# IA_MPUSS register map
Vendor: Texas Instruments
Peripheral module from a debugger description file (folder omap36xx).
Registers are 64-bit, read-only, reset 0x0 unless marked. A register's access mark holds for its fields unless they carry their own. Offsets are as the file gives them; lines under a group give offsets from that group; [hi:lo] are bit positions; {n}, {i} and the like mark numbered series; 'fields as' and 'values as' point back to an identical list; <NAME> marks a mode.

## IA_MPUSS
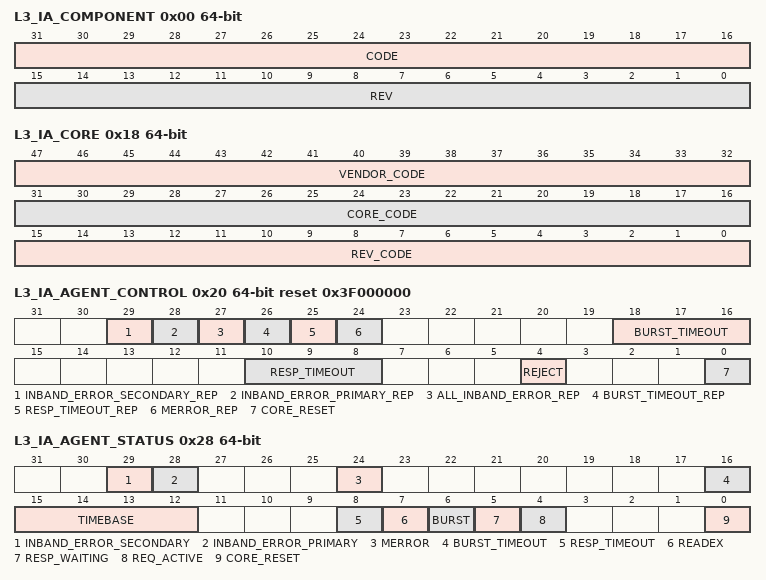
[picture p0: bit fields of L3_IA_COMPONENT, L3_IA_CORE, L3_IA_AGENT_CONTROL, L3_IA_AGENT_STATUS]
0x00 L3_IA_COMPONENT (reset mask 0xFFFFFFFF00000000) — Component register of IA
  [31:16] CODE — Component code
  [15:0] REV — Revision of the component
0x18 L3_IA_CORE (reset mask 0xFFFF000000000000) — Core register of L3 IA block
  [47:32] VENDOR_CODE
  [31:16] CORE_CODE
  [15:0] REV_CODE — Revision code
0x20 L3_IA_AGENT_CONTROL access per field reset 0x3F000000 — Agent control register of IA block
  [29] INBAND_ERROR_SECONDARY_REP rw — Reporting of in-band errors indicating debug error.Reserved for instances 3 to 12 Reserved R 0x0 .
    0=No special reporting; 1=Report error
  [28] INBAND_ERROR_PRIMARY_REP rw — Reporting of in-band errors indicating application error.
    0=No special reporting; 1=Report error
  [27] ALL_INBAND_ERROR_REP rw — Reporting of all in-band errors
    0=Only report errors that cannnot be reported in-band; 1=Report all in-band errors
  [26] BURST_TIMEOUT_REP rw — Open burst and ReadEx/Write timeout reporting
    0=No special reporting; 1=Report out of band
  [25] RESP_TIMEOUT_REP rw — Response timeout reportingReserved for instances 3, 6 to 10 and 12 Reserved R 0x00 .
    0=No special reporting; 1=Report out-of-band
  [24] MERROR_REP rw — MError reportingReserved for all instances except 14 (SGX) Reserved R 0x0000 .
    0=Suppress MError reporting; 1=Report MError
  [18:16] BURST_TIMEOUT rw — Response Timeout Bound:
    0=No timeout; 1=1x base cycles; 2=4x base cycles; 3=16x base cycles; 4=64x base cycles
  [10:8] RESP_TIMEOUT rw — Response Timeout Bound:Reserved for instances 3, 6 to 10 and 12 Reserved R 0x0 .
    values as BURST_TIMEOUT
  [4] REJECT rw — Request rejection control
    0=Normal operation; 1=Block requests from the initiator
  [0] CORE_RESET rw — Reset control for agent and reset control on core
    0=Core reset control inactive; 1=Core reset control active
0x28 L3_IA_AGENT_STATUS access per field — Agent Status Register
  [29] INBAND_ERROR_SECONDARY rw — Error Status for in-band errors indicating a debug error.Reserved for instances 3 to 12 Reserved R 0x0 .
    0=INBAND_ERROR_SECONDARY_0_r (No in-band error received); 0=INBAND_ERROR_SECONDARY_0_w (Ignored); 1=INBAND_ERROR_SECONDARY_1_r (In-band error received); 1=INBAND_ERROR_SECONDARY_1_w (Clear in-band error)
  [28] INBAND_ERROR_PRIMARY rw — Error Status for in-band errors indicating application Error
    0=INBAND_ERROR_PRIMARY_0_r (No in-band error received); 0=INBAND_ERROR_PRIMARY_0_w (Ignored); 1=INBAND_ERROR_PRIMARY_1_r (In-band error received); 1=INBAND_ERROR_PRIMARY_1_w (Clear in-band error)
  [24] MERROR ro — MErrorReserved for all instances except 14 (SGX) Reserved R 0x0000 .
    0=No Merror reported; 1=Merror asserted
  [16] BURST_TIMEOUT ro — Status of open burst and
  [15:12] TIMEBASE ro — Observation of timebase signals for internal verification
  [8] RESP_TIMEOUT ro — Response timeout statusReserved for instances 3, 6 to 10 and 12 Reserved R 0 .
  [7] READEX ro — Status of ReadEx/Write
  [6] BURST ro — Status of open burst
  [5] RESP_WAITING ro — Response WaitingReserved for instance 3,5,7 and 8 Reserved R 0 .
  [4] REQ_ACTIVE ro — Requests outstanding
  [0] CORE_RESET ro — Reset input from core interface
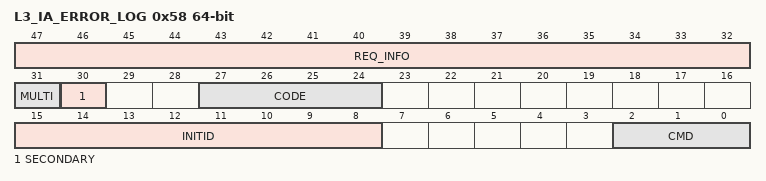
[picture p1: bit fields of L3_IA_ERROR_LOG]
0x58 L3_IA_ERROR_LOG access per field — Error log register of IA block
  [47:32] REQ_INFO ro — MReqInfo bits of command that caused the error
  [31] MULTI rw — Multiple Errors
    0=MULTI_0_w (Ignored); 0=MULTI_0_r (Multiple error not seen); 1=MULTI_1_w (Clear MULTI flag); 1=MULTI_1_r (Multiple error seen)
  [30] SECONDARY rw — Indicates whether error was primary or secondary
    0=SECONDARY_0_w (Ignored); 0=SECONDARY_0_r (Primary Error); 1=SECONDARY_1_w (Reset SECONDARY field); 1=SECONDARY_1_r (Secondary Error)
  [27:24] CODE rw — Error code
  [15:8] INITID ro — Initiator ID from which the command was launched. See.
  [2:0] CMD ro — Command that caused the error
0x60 L3_IA_ERROR_LOG_ADDR — Error log address register of IA block
  [31:0] ADDR — Address of the command that caused the error
